# SAM9X75D1GN2 device description
Architecture: ARM926EJ-S; Family: SAM9; Series: SAM9X7
Registers are 32-bit, read-write, reset 0x0 unless marked. A register's access mark holds for its fields unless they carry their own. Offsets are from the block's base; [hi:lo] are bit positions; {n}, {i} and the like mark numbered series.

## LCDC (part 1 of 2) — LCD Controller
Instances: XLCDC 0xF8038000
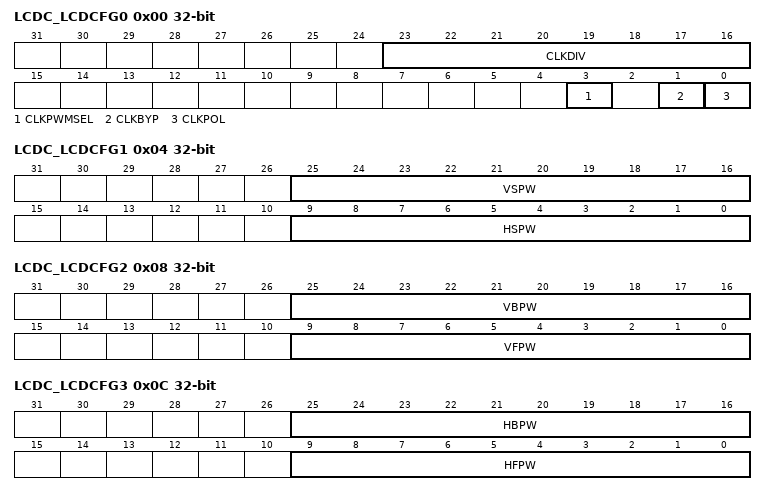
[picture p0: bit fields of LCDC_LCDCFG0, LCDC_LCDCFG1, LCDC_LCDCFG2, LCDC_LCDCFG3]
0x00 LCDC_LCDCFG0 — Configuration Register 0
  [23:16] CLKDIV — LCDC Clock Divider
  [3] CLKPWMSEL — LCDC PWM Clock Source Selection
    0=The slow clock is selected and feeds the PWM module; 1=The peripheral clock (MCK) is selected and feeds the PWM module
  [1] CLKBYP — LCDC Pixel Clock Divider Bypass
    0=Pixel clock divider is not bypassed. LCDC_PCK is defined with CLKDIV parameter.; 1=Pixel clock divider is bypassed. LCDC_PCK = GCLK clock
  [0] CLKPOL — LCDC Clock Polarity
    0=Data/Control signals are launched on the rising edge of the pixel clock; 1=Data/Control signals are launched on the falling edge of the pixel clock
0x04 LCDC_LCDCFG1 — Configuration Register 1
  [25:16] VSPW — Vertical Synchronization Pulse Width
  [9:0] HSPW — Horizontal Synchronization Pulse Width
0x08 LCDC_LCDCFG2 — Configuration Register 2
  [25:16] VBPW — Vertical Back Porch Width
  [9:0] VFPW — Vertical Front Porch Width
0x0C LCDC_LCDCFG3 — Configuration Register 3
  [25:16] HBPW — Horizontal Back Porch Width
  [9:0] HFPW — Horizontal Front Porch Width
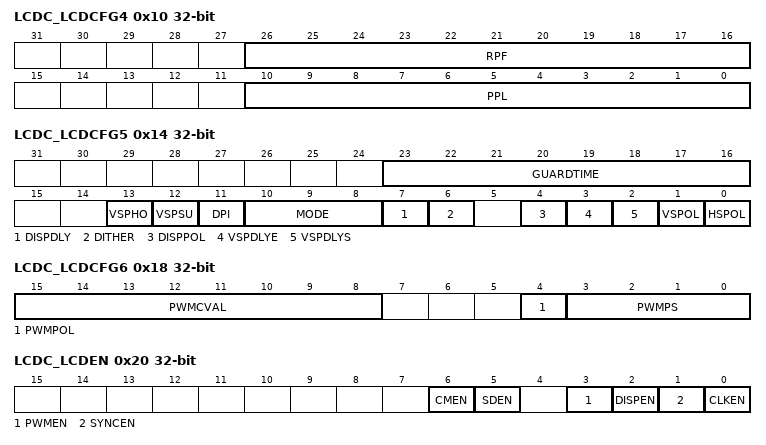
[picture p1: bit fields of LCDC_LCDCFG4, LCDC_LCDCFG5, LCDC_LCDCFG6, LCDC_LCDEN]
0x10 LCDC_LCDCFG4 — Configuration Register 4
  [26:16] RPF — Number of Active Row Per Frame
  [10:0] PPL — Number of Pixels Per Line
0x14 LCDC_LCDCFG5 — Configuration Register 5
  [23:16] GUARDTIME — LCD Display Guard Time
  [13] VSPHO — LCDC Vertical Synchronization Pulse Hold Configuration
    0=The vertical synchronization pulse is asserted synchronously with horizontal pulse edge; 1=The vertical synchronization pulse is held active one pixel clock cycle after the horizontal pulse
  [12] VSPSU — LCDC Vertical Synchronization Pulse Setup Configuration
    0=The vertical synchronization pulse is asserted synchronously with horizontal pulse edge; 1=The vertical synchronization pulse is asserted one pixel clock cycle before the horizontal pulse
  [11] DPI — Display Pixel Interface Compatible Mode
    0=Legacy pixel mapping; 1=Activates the DPI compliant pixel stream. See field MODE: LCDC Output Mode
  [10:8] MODE — LCDC Output Mode
    0=OUTPUT_12BPP (LCD Output mode is set to 12 bits per pixel); 0=OUTPUT_DPI_16BPPCFG1 (LCD Output mode is set to 16 bits per pixel Configuration 1); 1=OUTPUT_16BPP (LCD Output mode is set to 16 bits per pixel); 1=OUTPUT_DPI_16BPPCFG2 (LCD Output mode is set to 16 bits per pixel Configuration 2); 2=OUTPUT_18BPP (LCD Output mode is set to 18 bits per pixel); 2=OUTPUT_DPI_16BPPCFG3 (LCD Output mode is set to 16 bits per pixel Configuration 3); 3=OUTPUT_24BPP (LCD Output mode is set to 24 bits per pixel); 3=OUTPUT_DPI_18BPPCFG1 (LCD Output mode is set to 18 bits per pixel Configuration 1); 4=OUTPUT_DPI_18BPPCFG2 (LCD Output mode is set to 18 bits per pixel Configuration 2); 5=OUTPUT_DPI_24BPP (LCD Output mode is set to 24 bits per pixel)
  [7] DISPDLY — LCDC Display Power Signal Synchronization
    0=The LCDC_DISP signal is asserted synchronously with the second active edge of the horizontal pulse; 1=The LCDC_DISP signal is asserted asynchronously with both edges of the horizontal pulse
  [6] DITHER — LCDC Dithering
    0=Dithering logical unit is disabled; 1=Dithering logical unit is activated
  [4] DISPPOL — Display Signal Polarity
    0=Active high; 1=Active low
  [3] VSPDLYE — Vertical Synchronization Pulse End
    0=The second active edge of the vertical synchronization pulse is synchronous with the second edge of the horizontal pulse; 1=The second active edge of the vertical synchronization pulse is synchronous with the first edge of the horizontal pulse
  [2] VSPDLYS — Vertical Synchronization Pulse Start
    0=The first active edge of the vertical synchronization pulse is synchronous with the second edge of the horizontal pulse; 1=The first active edge of the vertical synchronization pulse is synchronous with the first edge of the horizontal pulse
  [1] VSPOL — Vertical Synchronization Pulse Polarity
    0=Active high; 1=Active low
  [0] HSPOL — Horizontal Synchronization Pulse Polarity
    0=Active high; 1=Active low
0x18 LCDC_LCDCFG6 — Configuration Register 6
  [15:8] PWMCVAL — LCDC PWM Compare Value
  [4] PWMPOL — LCDC PWM Signal Polarity
    0=The output pulses are low level; 1=The output pulses are high level (the output is high whenever the value in the counter is less than the value PWMCVAL)
  [3:0] PWMPS — PWM Clock Prescaler
    0=DIV_1 (The counter advances at a rate of fCOUNTER = fPWM_SELECTED_CLOCK); 1=DIV_2 (The counter advances at a rate of fCOUNTER = fPWM_SELECTED_CLOCK/2); 2=DIV_4 (The counter advances at a rate of fCOUNTER = fPWM_SELECTED_CLOCK/4); 3=DIV_8 (The counter advances at a rate of fCOUNTER = fPWM_SELECTED_CLOCK/8); 4=DIV_16 (The counter advances at a rate of fCOUNTER = fPWM_SELECTED_CLOCK/16); 5=DIV_32 (The counter advances at a of rate fCOUNTER = fPWM_SELECTED_CLOCK/32); 6=DIV_64 (The counter advances at a of rate fCOUNTER = fPWM_SELECTED_CLOCK/64); 7=DIV_128 (The counter advances at a of rate fCOUNTER = fPWM_SELECTED_CLOCK/128); 8=DIV_256 (The counter advances at a of rate fCOUNTER = fPWM_SELECTED_CLOCK/256); 9=DIV_512 (The counter advances at a of rate fCOUNTER = fPWM_SELECTED_CLOCK/512); 10=DIV_1024 (The counter advances at a of rate fCOUNTER = fPWM_SELECTED_CLOCK/1024); 11=DIV_2048 (The counter advances at a of rate fCOUNTER = fPWM_SELECTED_CLOCK/2048); 12=DIV_4096 (The counter advances at a of rate fCOUNTER = fPWM_SELECTED_CLOCK/4096); 13=DIV_8192 (The counter advances at a of rate fCOUNTER = fPWM_SELECTED_CLOCK/8192); 14=DIV_16384 (The counter advances at a of rate fCOUNTER = fPWM_SELECTED_CLOCK/16384); 15=DIV_32768 (The counter advances at a of rate fCOUNTER = fPWM_SELECTED_CLOCK/32768)
0x1C LCDC_LCDCFG7 — Configuration Register 7
  [10:0] ROW — Row Identifier For Row Interrupt Signal
0x20 LCDC_LCDEN wo reset not defined (atomic set of LCDC_LCDSR) — Enable Register
  [6] CMEN — Color Mode Signal Enable
    0=No effect; 1=Sets the color mode signal (lcd_cm) to one. If a rising edge is generated, signals the MIPI DSI host to send a "Color Mode On" command to the LCD screen when the MIPI output interface is selected.
  [5] SDEN — Shutdown Signal Enable
    0=No effect; 1=Sets the shutdown signal (lcd_sd) to zero (turns on the display)
  [3] PWMEN — LCDC Pulse Width Modulation Enable
    0=No effect; 1=PWM is enabled
  [2] DISPEN — LCDC DISP Signal Enable
    0=No effect; 1=LCDC_DISP signal is generated
  [1] SYNCEN — LCDC Horizontal and Vertical Synchronization Enable
    0=No effect; 1=Both horizontal and vertical synchronization (LCD_VSYNC and LCD_HSYNC) signals are generated
  [0] CLKEN — LCDC Pixel Clock Enable
    0=No effect; 1=Pixel clock logical unit is activated
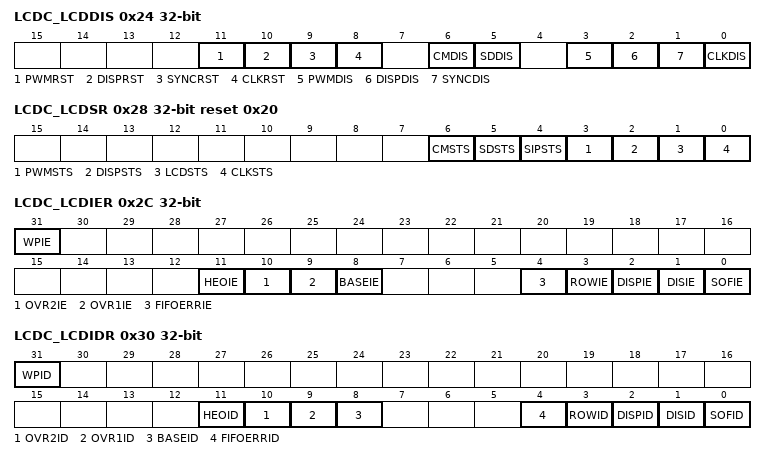
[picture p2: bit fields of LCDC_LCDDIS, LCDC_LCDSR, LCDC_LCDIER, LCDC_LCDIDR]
0x24 LCDC_LCDDIS wo reset not defined (atomic clear of LCDC_LCDSR) — Disable Register
  [11] PWMRST — LCDC PWM Reset
    0=No effect; 1=Resets the PWM module immediately. The duty cycle may be violated.
  [10] DISPRST — LCDC DISP Signal Reset
    0=No effect; 1=Resets the DISP signal immediately
  [9] SYNCRST — LCDC Horizontal and Vertical Synchronization Reset
    0=No effect; 1=Resets the timing engine immediately. The horizontal and vertical pulse widths are both violated.
  [8] CLKRST — LCDC Clock Reset
    0=No effect; 1=Resets the pixel clock generator module immediately. The pixel clock duty cycle may be violated.
  [6] CMDIS — Color Mode Signal Disable
    0=No effect; 1=Sets the color mode signa (lcd_cm) to zero. If a falling edge is generated, signals the MIPI DSI host to send a "Color Mode Off" command to the LCD screen when the MIPI output interface is selected).
  [5] SDDIS — Shutdown Signal Disable
    0=No effect; 1=Sets the shutdown signal (lcd_sd) to one (turns off the display)
  [3] PWMDIS — LCDC Pulse Width Modulation Disable
    0=No effect; 1=Disables the pulse width modulation signal after the end of the frame
  [2] DISPDIS — LCDC DISP Signal Disable
    0=No effect; 1=Disables the DISP signal after the end of the frame
  [1] SYNCDIS — LCDC Horizontal and Vertical Synchronization Disable
    0=No effect; 1=Disables the synchronization signals after the end of the frame
  [0] CLKDIS — LCDC Pixel Clock Disable
    0=No effect; 1=Disables the pixel clock after the end of the frame
0x28 LCDC_LCDSR ro reset 0x20 — Status Register
  [6] CMSTS — Color Mode Signal Status
    0=Color mode signal output is zero; 1=Color mode signal output is one
  [5] SDSTS — Shutdown Signal Status
    0=Shutdown signal output is zero; 1=Shutdown signal output is one
  [4] SIPSTS — Synchronization In Progress
    0=Clock domain synchronization is terminated; 1=Synchronization is in progress. Access to the registers LCDC_LCDCCFG[0..7], LCDC_LCDEN and LCDC_LCDDIS has no effect.
  [3] PWMSTS — LCDC PWM Signal Status
    0=PWM is disabled; 1=PWM signal is activated
  [2] DISPSTS — LCDC DISP Signal Status
    0=DISP is disabled; 1=DISP signal is activated
  [1] LCDSTS — LCDC Synchronization Status
    0=Timing engine is disabled; 1=Timing engine is running
  [0] CLKSTS — Clock Status
    0=Pixel clock is disabled; 1=Pixel clock is running
0x2C LCDC_LCDIER wo reset not defined (atomic set of LCDC_LCDIMR) — Interrupt Enable Register
  [31] WPIE — Write Protection Interrupt Enable
  [11] HEOIE — High-End Overlay Interrupt Enable
  [10] OVR2IE — Overlay 2 Interrupt Enable
  [9] OVR1IE — Overlay 1 Interrupt Enable
  [8] BASEIE — Base Layer Interrupt Enable
  [4] FIFOERRIE — Output FIFO Error Interrupt Enable
  [3] ROWIE — Row Interrupt Enable
  [2] DISPIE — Power-up/Power-down Sequence Terminated Interrupt Enable
  [1] DISIE — LCD Disable Interrupt Enable
  [0] SOFIE — Start of Frame Interrupt Enable
0x30 LCDC_LCDIDR wo reset not defined (atomic clear of LCDC_LCDIMR) — Interrupt Disable Register
  [31] WPID — Write Protection Interrupt Disable
  [11] HEOID — High-End Overlay Interrupt Disable
  [10] OVR2ID — Overlay 2 Interrupt Disable
  [9] OVR1ID — Overlay 1 Interrupt Disable
  [8] BASEID — Base Layer Interrupt Disable
  [4] FIFOERRID — Output FIFO Error Interrupt Disable
  [3] ROWID — Row Interrupt Disable
  [2] DISPID — Power-up/Power-down Sequence Terminated Interrupt Disable
  [1] DISID — LCD Disable Interrupt Disable
  [0] SOFID — Start of Frame Interrupt Disable
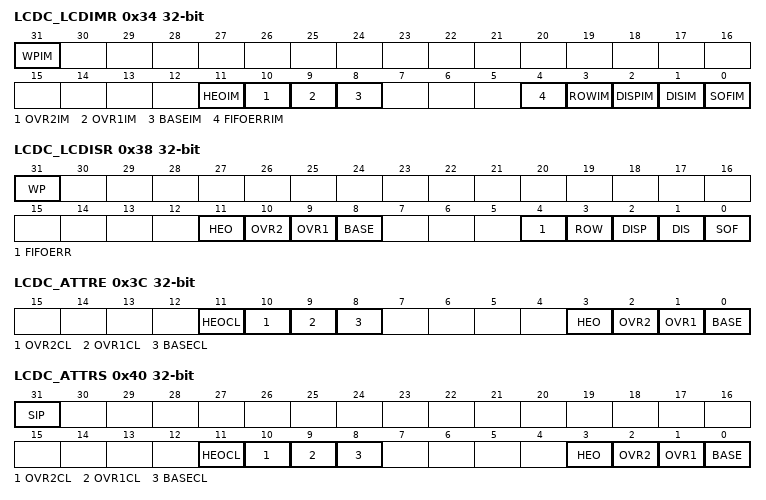
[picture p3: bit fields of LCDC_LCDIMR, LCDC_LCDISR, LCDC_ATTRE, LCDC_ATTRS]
0x34 LCDC_LCDIMR ro — Interrupt Mask Register
  [31] WPIM — Write Protection Interrupt Mask
  [11] HEOIM — High-End Overlay Interrupt Mask
  [10] OVR2IM — Overlay 2 Interrupt Mask
  [9] OVR1IM — Overlay 1 Interrupt Mask
  [8] BASEIM — Base Layer Interrupt Mask
  [4] FIFOERRIM — Output FIFO Error Interrupt Mask
  [3] ROWIM — Row Interrupt Mask
  [2] DISPIM — Power-up/Power-down Sequence Terminated Interrupt Mask
  [1] DISIM — LCD Disable Interrupt Mask
  [0] SOFIM — Start of Frame Interrupt Mask
0x38 LCDC_LCDISR ro — Interrupt Status Register
  [31] WP — Write Protection Interrupt Status
    0=No Write Protection interrupt detected since last read of LCDC_LCDISR; 1=Indicates that Write Protection error has been detected. This flag is reset after a read operation.
  [11] HEO — High-End Overlay Raw Interrupt Status
    0=No High-End layer interrupt detected since last read of LCDC_HEOISR; 1=Indicates that a High-End layer interrupt is pending. This flag is reset as soon as the LCDC_HEOISR is read.
  [10] OVR2 — Overlay 2 Raw Interrupt Status
    0=No Overlay 2 layer interrupt detected since last read of LCDC_OVR2ISR; 1=Indicates that an Overlay 2 layer interrupt is pending. This flag is reset as soon as the LCDC_OVR2ISR is read.
  [9] OVR1 — Overlay 1 Raw Interrupt Status
    0=No Overlay 1 layer interrupt detected since last read of LCDC_OVR1ISR; 1=Indicates that an Overlay 1 layer interrupt is pending. This flag is reset as soon as the LCDC_OVR1ISR is read.
  [8] BASE — Base Layer Raw Interrupt Status
    0=No base layer interrupt detected since last read of LCDC_BASEISR; 1=Indicates that a base layer interrupt is pending. This flag is reset as soon as the LCDC_BASEISR is read.
  [4] FIFOERR — Output FIFO Error
    0=No underflow has occurred in the output FIFO since last read of LCDC_LCDISR; 1=Indicates that an underflow has occurred in the output FIFO. This flag is reset after a read operation.
  [3] ROW — Row Interrupt Status
    0=No detection since last read of the LCDC_LCDCISR; 1=Indicates that a row event has been detected. This flag is reset after a read operation.
  [2] DISP — Power-up/Power-down Sequence Terminated Interrupt Status
    0=Power-up sequence or power-down sequence has not yet terminated; 1=Indicates the power-up sequence or power-down sequence has terminated. This flag is reset after a read operation.
  [1] DIS — LCD Disable Interrupt Status
    0=Horizontal and vertical timing generator has not yet been disabled; 1=Indicates that the horizontal and vertical timing generator has been disabled. This flag is reset after a read operation.
  [0] SOF — Start of Frame Interrupt Status
    0=No detection since last read of LCDC_LCDISR; 1=Indicates that a start of frame event has been detected. This flag is reset after a read operation.
0x3C LCDC_ATTRE wo reset not defined — Attribute Enable Register
  [11] HEOCL — High-End Overlay Update Color LUT
    0=No effect; 1=DMA update request for the HEO layer CLUT content
  [10] OVR2CL — Overlay 2 Update Color LUT
    0=No effect; 1=DMA update request for the OVR2 layer CLUT content
  [9] OVR1CL — Overlay 1 Update Color LUT
    0=No effect; 1=DMA update request for the OVR1 layer CLUT content
  [8] BASECL — Base Layer Update Color LUT
    0=No effect; 1=DMA update request for the base layer CLUT content
  [3] HEO — High-End Overlay Update Attribute
    0=No effect; 1=Updates the HEO window attribute
  [2] OVR2 — Overlay 2 Update Attribute
    0=No effect; 1=Updates the OVR2 window attribute
  [1] OVR1 — Overlay 1 Update Attribute
    0=No effect; 1=Updates the OVR1 window attribute
  [0] BASE — Base Layer Update Attribute
    0=No effect; 1=Updates the base window attributes
0x40 LCDC_ATTRS ro — Attribute Status Register
  [31] SIP — Synchronization In Progress
    0=Clock domain synchronization is terminated; 1=Synchronization is in progress. Access to LCDC_ATTRE has no effect.
  [11] HEOCL — High-End Overlay Color Table Status
    0=No effect; 1=Indicates that an update request is pending for the High-end Overlay CLUT
  [10] OVR2CL — Overlay 2 Color Table Status
    0=No effect; 1=Indicates that an update request is pending for the Overlay 2 CLUT
  [9] OVR1CL — Overlay 1 Color Table Status
    0=No effect; 1=Indicates that an update request is pending for the Overlay 1 CLUT
  [8] BASECL — Base Layer Color Table Status
    0=No effect; 1=Indicates that an update request is pending for the base CLUT
  [3] HEO — High-End Overlay Update Status
    0=No effect; 1=Indicates that an update request is pending for High-end Overlay
  [2] OVR2 — Overlay 2 Update Status
    0=No effect; 1=Indicates that an update request is pending for the Overlay 2 layer
  [1] OVR1 — Overlay 1 Update Status
    0=No effect; 1=Indicates that an update request is pending for the Overlay 1 layer
  [0] BASE — Base Layer Update Status
    0=No effect; 1=Indicates that an update request is pending for the base layer
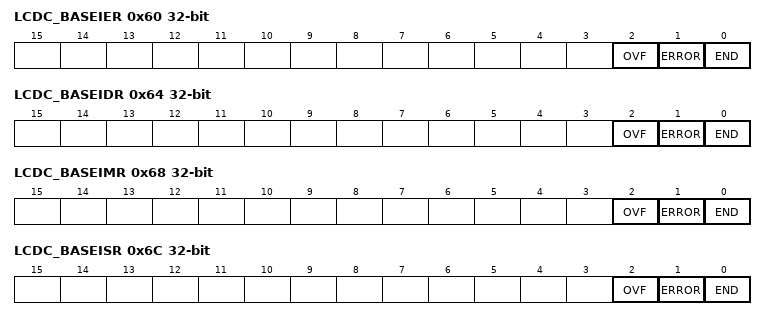
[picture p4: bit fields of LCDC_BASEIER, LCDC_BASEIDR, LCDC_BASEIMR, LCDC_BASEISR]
0x60 LCDC_BASEIER wo reset not defined (atomic set of LCDC_BASEIMR) — Base Layer Interrupt Enable Register
  [2] OVF — Overflow Interrupt Enable
  [1] ERROR — Transfer Error Detected Interrupt Enable
  [0] END — End of Frame DMA Transfer Interrupt Enable
0x64 LCDC_BASEIDR wo reset not defined (atomic clear of LCDC_BASEIMR) — Base Layer Interrupt Disable Register
  [2] OVF — Overflow Interrupt Disable
  [1] ERROR — Transfer Error Interrupt Disable
  [0] END — End of Frame DMA Transfer Interrupt Disable
0x68 LCDC_BASEIMR ro — Base Layer Interrupt Mask Register
  [2] OVF — Overflow Interrupt Mask
  [1] ERROR — Transfer Error Interrupt Mask
  [0] END — End of Frame DMA Transfer Interrupt Mask
0x6C LCDC_BASEISR ro — Base Layer Interrupt Status Register
  [2] OVF — Overflow Detected
    0=No overflow occurred since last read of LCDC_BASEISR; 1=An overflow occurred, at least one DMA transfer is still running at the End Of Frame. This flag is reset after a read operation.
  [1] ERROR — Transfer Error Detected
    0=No system bus error has been detected since the last read of LCDC_BASEISR; 1=A system bus error has been detected. This flag is reset after a read operation.
  [0] END — End of Frame DMA Transfer
    0=No end of frame DMA transfer has been detected since last read of LCDC_BASEISR; 1=End of transfer has been detected. This flag is reset after a read operation.
0x70 LCDC_BASEEN — Base Layer Enable Register
  [0] ENABLE — Base Layer Enable
    0=The layer is disabled; 1=The layer is enabled
0x74 LCDC_BASECLA — Base Layer Color Table Address Register
  [31:2] CLA — Base Layer CLUT Address
0x78 LCDC_BASEFBA — Base Layer Frame Buffer Address Register
  [31:2] FBA — Frame Buffer Address
0x7C LCDC_BASECFG0 — Base Layer Configuration Register 0
  [6:4] BLEN — System Bus Burst Length
    0=INCR1 (System bus access is started as soon as there is enough space in the FIFO to store one data.); 1=INCR4 (System bus access is started as soon as there is enough space in the FIFO to store a total amount of 4 data. A system bus INCR4 Burst is used by default. INCR1 is used for bursts less than 4.); 2=INCR8 (System bus access is started as soon as there is enough space in the FIFO to store a total amount of 8 data. A system bus INCR8 Burst is used by default. INCR4 bursts are used for bursts of 4 beats.INCR1 is used for bursts less than 4.); 3=INCR16 (System bus access is started as soon as there is enough space in the FIFO to store a total amount of 16 data. A system bus INCR16 Burst is used by default. INCR8 and INCR4 bursts are respectively used for bursts of 8 and 4 beats.INCR1 is used for bursts less than 4.); 4=INCR32 (System bus access is started as soon as there is enough space in the FIFO to store a total amount of 32 data. A system bus INCR32 Burst is used by default. INCR16, INCR8 and INCR4 bursts are respectively used for bursts of 16, 8 and 4 beats. INCR1 is used for bursts less than 4.)
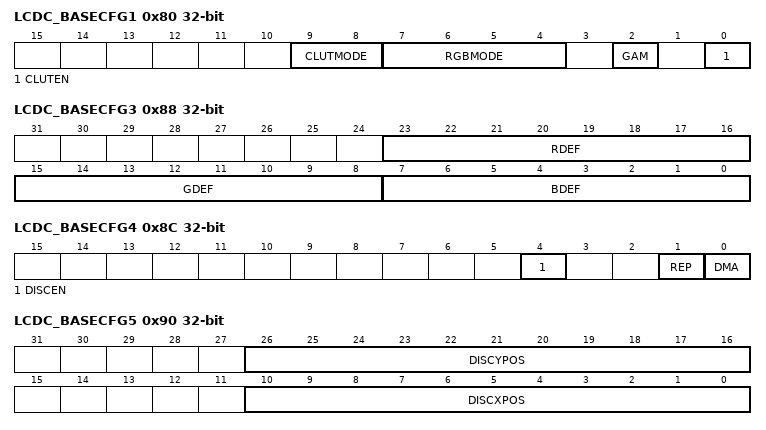
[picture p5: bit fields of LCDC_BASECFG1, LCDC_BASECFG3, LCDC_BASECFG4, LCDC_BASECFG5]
0x80 LCDC_BASECFG1 — Base Layer Configuration Register 1
  [9:8] CLUTMODE — CLUT Mode Input Selection
    0=CLUT_1BPP (CLUT mode set to 1 bit per pixel); 1=CLUT_2BPP (CLUT mode set to 2 bits per pixel); 2=CLUT_4BPP (CLUT mode set to 4 bits per pixel); 3=CLUT_8BPP (CLUT mode set to 8 bits per pixel)
  [7:4] RGBMODE — RGB Mode Input Selection
    0=12BPP_RGB_444; 1=16BPP_ARGB_4444; 2=16BPP_RGBA_4444; 3=16BPP_RGB_565; 4=16BPP_ARGB_1555; 5=18BPP_RGB_666; 6=18BPP_RGB_666PACKED; 7=19BPP_ARGB_1666; 8=19BPP_ARGB_PACKED (19 bpp ARGB 1666 PACKED); 9=24BPP_RGB_888; 10=24BPP_RGB_888_PACKED; 11=25BPP_ARGB_1888; 12=32BPP_ARGB_8888; 13=32BPP_RGBA_8888
  [2] GAM — Gamma Correction
    0=Gamma correction is disabled; 1=Gamma correction is activated
  [0] CLUTEN — CLUT Mode Enable
    0=RGB mode is selected; 1=CLUT mode is selected
0x84 LCDC_BASECFG2 — Base Layer Configuration Register 2
  [31:0] XSTRIDE — Horizontal Stride
0x88 LCDC_BASECFG3 — Base Layer Configuration Register 3
  [23:16] RDEF — Red Default
  [15:8] GDEF — Green Default
  [7:0] BDEF — Blue Default
0x8C LCDC_BASECFG4 — Base Layer Configuration Register 4
  [4] DISCEN — Discard Area Enable
    0=The whole frame is retrieved from memory; 1=The DMA channel discards the area located at screen coordinates {DISCXPOS, DISCYPOS}
  [1] REP — Use Replication Logic to Expand RGB Color to 24 Bits
    0=When the selected pixel depth is less than 24 bpp, the pixel is shifted and LSBs are set to 0; 1=When the selected pixel depth is less than 24 bpp, the pixel is shifted and the LSB replicates the MSB
  [0] DMA — Use DMA Data Path
    0=The default color is used on the base layer; 1=The DMA channel retrieves the pixel stream from the memory
0x90 LCDC_BASECFG5 — Base Layer Configuration Register 5
  [26:16] DISCYPOS — Discard Area Vertical Coordinate
  [10:0] DISCXPOS — Discard Area Horizontal Coordinate
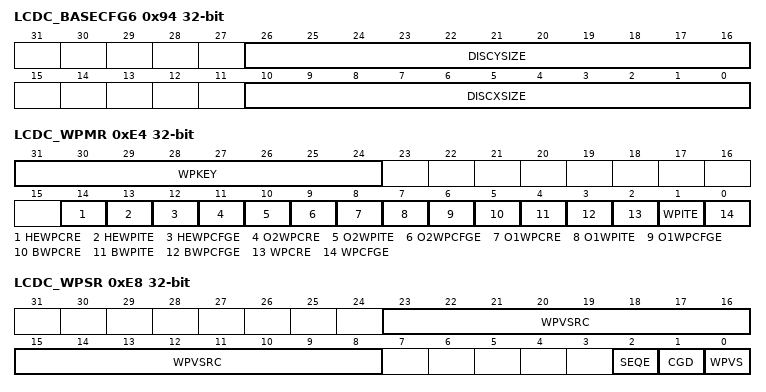
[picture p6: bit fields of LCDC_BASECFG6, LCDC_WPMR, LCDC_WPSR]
0x94 LCDC_BASECFG6 — Base Layer Configuration Register 6
  [26:16] DISCYSIZE — Discard Area Vertical Size
  [10:0] DISCXSIZE — Discard Area Horizontal Size
0xE4 LCDC_WPMR — Write Protection Mode Register
  [31:24] WPKEY — Write Protection Key Password
    88=PASSWD (Writing any other value in this field aborts the write operation of the WPCFGE, WPITE, WPCRE bits. Always reads as 0.)
  [14] HEWPCRE — High-End Overlay Write Protection Control Registers Enable
    0=Disables the write protection of High-End Overlay Control registers if WPKEY corresponds to 0x58 ("X" in ASCII); 1=Enables the write protection of High-End Overlay Control registers if WPKEY corresponds to 0x58 ("X" in ASCII)
  [13] HEWPITE — High-End Overlay Write Protection Interrupt Registers Enable
    0=Disables the write protection of High-End Overlay Interrupt Enable/Disable registers if WPKEY corresponds to 0x58 ("X" in ASCII); 1=Enables the write protection of High-End Overlay Interrupt Enable/Disable registers if WPKEY corresponds to 0x58 ("X" in ASCII)
  [12] HEWPCFGE — High-End Overlay Write Protection Configuration Registers Enable
    0=Disables the write protection of High-End Overlay Configuration registers if WPKEY corresponds to 0x58 ("X" in ASCII); 1=Enables the write protection of High-End Overlay Configuration registers if WPKEY corresponds to 0x58 ("X" in ASCII)
  [11] O2WPCRE — Overlay 2 Write Protection Control Registers Enable
    0=Disables the write protection of Overlay 2 Control registers if WPKEY corresponds to 0x58 ("X" in ASCII); 1=Enables the write protection of Overlay 2 Control registers if WPKEY corresponds to 0x58 ("X" in ASCII)
  [10] O2WPITE — Overlay 2 Write Protection Interrupt Registers Enable
    0=Disables the write protection of Overlay 2 Interrupt Enable/Disable registers if WPKEY corresponds to 0x58 ("X" in ASCII); 1=Enables the write protection of Overlay 2 Interrupt Enable/Disable registers if WPKEY corresponds to 0x58 ("X" in ASCII)
  [9] O2WPCFGE — Overlay 2 Write Protection Configuration Registers Enable
    0=Disables the write protection of Overlay 2 Configuration registers if WPKEY corresponds to 0x58 ("X" in ASCII); 1=Enables the write protection of Overlay 2 Configuration registers if WPKEY corresponds to 0x58 ("X" in ASCII)
  [8] O1WPCRE — Overlay 1 Write Protection Control Registers Enable
    0=Disables the write protection of Overlay 1 Control registers if WPKEY corresponds to 0x58 ("X" in ASCII); 1=Enables the write protection of Overlay 1 Control registers if WPKEY corresponds to 0x58 ("X" in ASCII)
  [7] O1WPITE — Overlay 1 Write Protection Interrupt Registers Enable
    0=Disables the write protection of Overlay 1 Interrupt Enable/Disable registers if WPKEY corresponds to 0x58 ("X" in ASCII); 1=Enables the write protection of Overlay 1 Interrupt Enable/Disable registers if WPKEY corresponds to 0x58 ("X" in ASCII)
  [6] O1WPCFGE — Overlay 1 Write Protection Configuration Registers Enable
    0=Disables the write protection of Overlay 1 Configuration registers if WPKEY corresponds to 0x58 ("X" in ASCII); 1=Enables the write protection of Overlay 1 Configuration registers if WPKEY corresponds to 0x58 ("X" in ASCII)
  [5] BWPCRE — Base Layer Write Protection Control Registers Enable
    0=Disables the write protection of base layer Control registers if WPKEY corresponds to 0x58 ("X" in ASCII); 1=Enables the write protection of base layer Control registers if WPKEY corresponds to 0x58 ("X" in ASCII)
  [4] BWPITE — Base Layer Write Protection Interrupt Registers Enable
    0=Disables the write protection of base layer Interrupt Enable/Disable registers if WPKEY corresponds to 0x58 ("X" in ASCII); 1=Enables the write protection of base layer Interrupt Enable/Disable registers if WPKEY corresponds to 0x58 ("X" in ASCII)
  [3] BWPCFGE — Base Layer Write Protection Configuration Registers Enable
    0=Disables the write protection of base layer Configuration registers if WPKEY corresponds to 0x58 ("X" in ASCII); 1=Enables the write protection of base layer Configuration registers if WPKEY corresponds to 0x58 ("X" in ASCII)
  [2] WPCRE — Write Protection Control Registers Enable
    0=Disables the write protection of LCDC Control registers if WPKEY corresponds to 0x58 ("X" in ASCII); 1=Enables the write protection of LCDC Control registers if WPKEY corresponds to 0x58 ("X" in ASCII)
  [1] WPITE — Write Protection Interrupt Registers Enable
    0=Disables the write protection of LCDC Interrupt Enable/Disable registers if WPKEY corresponds to 0x58 ("X" in ASCII); 1=Enables the write protection of LCDC Interrupt Enable/Disable registers if WPKEY corresponds to 0x58 ("X" in ASCII)
  [0] WPCFGE — Write Protection Configuration Registers Enable
    0=Disables the write protection of LCDC Configuration registers if WPKEY corresponds to 0x58 ("X" in ASCII); 1=Enables the write protection of LCDC Configuration registers if WPKEY corresponds to 0x58 ("X" in ASCII)
0xE8 LCDC_WPSR ro — Write Protection Status Register
  [23:8] WPVSRC — Write Protection Violation Source
  [2] SEQE — Internal Sequencer Error (cleared on read)
    0=No peripheral internal sequencer error has occurred since the last read of LCDC_WPSR; 1=A peripheral internal sequencer error has occurred since the last read of LCDC_WPSR. This flag can only be set under abnormal operating conditions.
  [1] CGD — Clock Glitch Detected (cleared on read)
    0=The clock monitoring circuitry has not been corrupted since the last read of LCDC_WPSR. Under normal operating conditions, this bit is always cleared.; 1=The clock monitoring circuitry has been corrupted since the last read of LCDC_WPSR. This flag can only be set in case of an abnormal clock signal waveform (glitch).
  [0] WPVS — Write Protection Violation Status
